# PCIE_0_ECC_CFG register map
Vendor: Texas Instruments
Peripheral module from a debugger description file (folder 66AK2G0x_66AK2G1x).
Registers are 32-bit, write-only, reset 0x0 unless marked. A register's access mark holds for its fields unless they carry their own. Offsets are as the file gives them; lines under a group give offsets from that group; [hi:lo] are bit positions; {n}, {i} and the like mark numbered series; 'fields as' and 'values as' point back to an identical list; <NAME> marks a mode.

## PCIE_0_ECC_CFG
0x00 PCIE_ECC_REVISION ro reset 0x4E100001
  [31:0] REV — TI internal data. Identifies revision of peripheral.
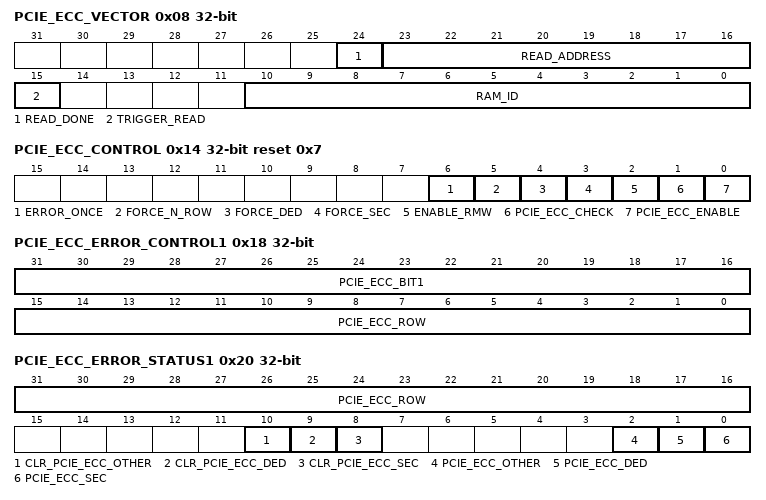
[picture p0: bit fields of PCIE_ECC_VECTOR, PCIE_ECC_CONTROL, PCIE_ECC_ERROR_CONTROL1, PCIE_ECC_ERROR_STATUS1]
0x08 PCIE_ECC_VECTOR access per field
  [24] READ_DONE ro — Status indicating that the serial VBUS read is complete
  [23:16] READ_ADDRESS rw — Read address. Can be any of the registers 0x10 - 0x24
  [15] TRIGGER_READ rw — Trigger a read operation to the specified read address that requires a serial VBUS access
  [10:0] RAM_ID rw — ECC RAM ID to select which ECC RAM to control or read status from
0x0C PCIE_ECC_MISC_STATUS access per field (reset mask 0xFFFFF800)
  [10:0] NUM_RAMS rw — Number of ECC RAMs serviced by the aggregator
0x10 PCIE_ECC_WRAPPER_REVISION ro reset 0x4E100001
  [31:0] REV — TI internal data. Identifies revision of peripheral.
0x14 PCIE_ECC_CONTROL access per field reset 0x7
  [6] ERROR_ONCE rw — If this bit is set, the force_sec/force_ded will inject an error to the specified row only once. The force_sec bit will be cleared once a writeback happens. If writeback is not enabled, this error will be cleared the cycle following the read when the data is corrected. For double-bit errors, the force_ded bit will be cleared the cycle following the double-bit error. Any subsequent reads will not force an error.
  [5] FORCE_N_ROW rw — Force single/double-bit error on the next RAM read
  [4] FORCE_DED rw — Force double-bit error. Cleared the cycle following the error if error_once is asserted.
  [3] FORCE_SEC rw — Force single-bit error. Cleared on a writeback or the cycle following the error if error_once is asserted
  [2] ENABLE_RMW rw — Enable read-modify-write on partial word writes
  [1] PCIE_ECC_CHECK rw — Enable ECC check. ECC is completely bypassed if both PCIE_ECC_enable and PCIE_ECC_check are 0
  [0] PCIE_ECC_ENABLE rw — Enable ECC generation
0x18 PCIE_ECC_ERROR_CONTROL1 rw
  [31:16] PCIE_ECC_BIT1 — Data bit that needs to be flipped when force_sec or force_ded is set
  [15:0] PCIE_ECC_ROW — Row address where force_sec or force_ded needs to be applied. This is ignored if force_n_row is set.
0x1C PCIE_ECC_ERROR_CONTROL2 access per field
  [15:0] PCIE_ECC_BIT2 rw — Data bit that needs to be flipped when force_ded is set
0x20 PCIE_ECC_ERROR_STATUS1 access not given
  [31:16] PCIE_ECC_ROW ro — Indicates the row/address where the single or double-bit error occurred
  [10] CLR_PCIE_ECC_OTHER — 1 indicates a pending double-bit error. Writing a 1 clears the status bit. (access W1toCl)
  [9] CLR_PCIE_ECC_DED — 1 indicates a pending successive single-bit error. Writing a 1 clears the status bit. (access W1toCl)
  [8] CLR_PCIE_ECC_SEC — 1 indicates a pending single-bit error. Writing a 1 clears the status bit. (access W1toCl)
  [2] PCIE_ECC_OTHER rw — 1 indicates that successive single-bit errors have occurred while a writeback is still pending. Software can also write a 1 to set the pending status.
  [1] PCIE_ECC_DED rw — 1 indicates a double-bit error. Software can also write a 1 to set the pending status.
  [0] PCIE_ECC_SEC rw — 1 indicates a single-bit error. Software can also write a 1 to set the pending status.
0x24 PCIE_ECC_ERROR_STATUS2 ro
  [15:0] PCIE_ECC_BIT1 — Indicates the data bit that is in error
0x3C PCIE_ECC_EOI access per field reset not defined
  [0] EOI_WR rw — Write to this register indicates that software has acknowledged the pending interrupt and the next interrupt can be sent to the host
{0x40+4i} PCIE_ECC_INT_STATUS_{i} ro (i=0..14)
  [31:0] BITMASK — Level interrupt status from each ECC RAM:
{0x80+4i} PCIE_ECC_INT_ENABLE_{i} (i=0..14)
  [31:0] BITMASK — Write 1 to enable interrupt from the associated ECC RAM
{0xC0+4i} PCIE_ECC_INT_CLEAR_{i} (i=0..14)
  [31:0] BITMASK — Write 1 to disable interrupt from the associated ECC RAM
